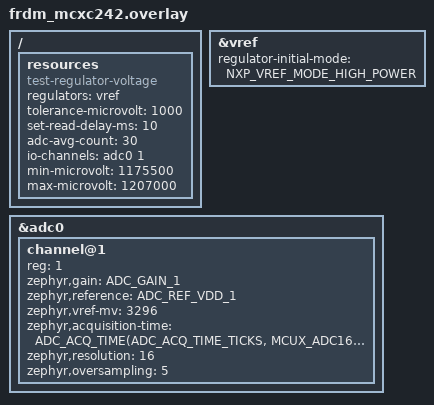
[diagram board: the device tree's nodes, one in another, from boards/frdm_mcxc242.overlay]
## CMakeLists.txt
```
# Copyright (c) 2022 Nordic Semiconductor ASA
# SPDX-License-Identifier: Apache-2.0

cmake_minimum_required(VERSION 3.28.0)
find_package(Zephyr REQUIRED HINTS $ENV{ZEPHYR_BASE})

project(regulator_voltage)

target_sources(app PRIVATE src/main.c)
```

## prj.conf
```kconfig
# Copyright (c) 2022 Nordic Semiconductor ASA
# SPDX-License-Identifier: Apache-2.0

CONFIG_ZTEST=y
CONFIG_ADC=y
CONFIG_REGULATOR=y
```

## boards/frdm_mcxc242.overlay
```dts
/*
 * Copyright 2025 NXP
 * SPDX-License-Identifier: Apache-2.0
 */

#include <zephyr/dt-bindings/regulator/nxp_vref.h>
#include <zephyr/dt-bindings/adc/mcux-adc16.h>

/* Connect J4-2 and J8-2 to test this case. */

/ {
	resources: resources {
		compatible = "test-regulator-voltage";
		regulators = <&vref>;
		tolerance-microvolt = <1000>;
		set-read-delay-ms = <10>;
		adc-avg-count = <30>;
		io-channels = <&adc0 1>;
		min-microvolt = <1175500>;
		max-microvolt = <1207000>;
	};
};

&vref {
	regulator-initial-mode = <NXP_VREF_MODE_HIGH_POWER>;
};

&adc0 {
	#address-cells = <1>;
	#size-cells = <0>;

	channel@1 {
		reg = <1>;
		zephyr,gain = "ADC_GAIN_1";
		zephyr,reference = "ADC_REF_VDD_1";
		zephyr,vref-mv = <3296>;
		zephyr,acquisition-time = <ADC_ACQ_TIME(ADC_ACQ_TIME_TICKS,
							MCUX_ADC16_ACQUISITION_TIME_24CYCLE)>;
		zephyr,resolution = <16>;
		zephyr,oversampling = <5>;
	};
};
```

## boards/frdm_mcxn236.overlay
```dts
/*
 * Copyright 2024-2025 NXP
 * SPDX-License-Identifier: Apache-2.0
 */

#include <zephyr/dt-bindings/adc/adc.h>
#include <zephyr/dt-bindings/adc/mcux-lpadc.h>
#include <zephyr/dt-bindings/regulator/nxp_vref.h>

/ {
	resources: resources {
		compatible = "test-regulator-voltage";
		regulators = <&vref>;
		tolerance-microvolt = <20000>;
		set-read-delay-ms = <1>;
		adc-avg-count = <10>;
		io-channels = <&lpadc0 0>;
		min-microvolt = <1000000>;
		max-microvolt = <2100000>;
	};
};

&vref {
	regulator-initial-mode = <NXP_VREF_MODE_HIGH_POWER>;
};

&lpadc0 {
	#address-cells = <1>;
	#size-cells = <0>;

	/* In this case, the LPADC reference source cannot be set to VREFO,
	 * switch the reference source to VDD_ANA. The user needs to measure the
	 * voltage of VDD_ANA pin to set the value of 'zephyr,vref-mv'.
	 */
	voltage-ref = <2>;

	channel@0 {
		reg = <0>;
		zephyr,gain = "ADC_GAIN_1";
		zephyr,reference = "ADC_REF_EXTERNAL0";
		/* VDD_ANA is not accurate to 3300mV, after measurement,
		 * the actual voltage is 3285mV.
		 */
		zephyr,vref-mv = <3285>;
		zephyr,acquisition-time = <ADC_ACQ_TIME(ADC_ACQ_TIME_TICKS, 7)>;
		zephyr,resolution = <12>;
		/* ADC0 channel 7 A-side is internally connected to VREFO. */
		zephyr,input-positive = <MCUX_LPADC_CH7A>;
	};
};
```

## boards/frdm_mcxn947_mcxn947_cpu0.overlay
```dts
/*
 * Copyright 2024-2025 NXP
 * SPDX-License-Identifier: Apache-2.0
 */

#include <zephyr/dt-bindings/adc/adc.h>
#include <zephyr/dt-bindings/adc/mcux-lpadc.h>
#include <zephyr/dt-bindings/regulator/nxp_vref.h>

/ {
	resources: resources {
		compatible = "test-regulator-voltage";
		regulators = <&vref>;
		tolerance-microvolt = <30000>;
		set-read-delay-ms = <1>;
		adc-avg-count = <10>;
		io-channels = <&lpadc0 0>;
		min-microvolt = <1000000>;
		max-microvolt = <2100000>;
	};
};

&vref {
	regulator-initial-mode = <NXP_VREF_MODE_HIGH_POWER>;
};

&lpadc0 {
	#address-cells = <1>;
	#size-cells = <0>;

	/* In this case, the LPADC reference source cannot be set to VREFO,
	 * switch the reference source to VDD_ANA. The user needs to measure the
	 * voltage of VDD_ANA pin to set the value of 'zephyr,vref-mv'.
	 */
	voltage-ref = <2>;

	channel@0 {
		reg = <0>;
		zephyr,gain = "ADC_GAIN_1";
		zephyr,reference = "ADC_REF_EXTERNAL0";
		/* VDD_ANA is not accurate to 3300mV, after measurement,
		 * the actual voltage is 3285mV.
		 */
		zephyr,vref-mv = <3285>;
		zephyr,acquisition-time = <ADC_ACQ_TIME(ADC_ACQ_TIME_TICKS, 7)>;
		zephyr,resolution = <12>;
		/* ADC0 channel 7 A-side is internally connected to VREFO. */
		zephyr,input-positive = <MCUX_LPADC_CH7A>;
	};
};
```

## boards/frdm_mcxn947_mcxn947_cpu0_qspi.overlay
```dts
/*
 * Copyright 2024-2025 NXP
 * SPDX-License-Identifier: Apache-2.0
 */

#include <zephyr/dt-bindings/adc/adc.h>
#include <zephyr/dt-bindings/adc/mcux-lpadc.h>
#include <zephyr/dt-bindings/regulator/nxp_vref.h>

/ {
	resources: resources {
		compatible = "test-regulator-voltage";
		regulators = <&vref>;
		tolerance-microvolt = <30000>;
		set-read-delay-ms = <1>;
		adc-avg-count = <10>;
		io-channels = <&lpadc0 0>;
		min-microvolt = <1000000>;
		max-microvolt = <2100000>;
	};
};

&vref {
	regulator-initial-mode = <NXP_VREF_MODE_HIGH_POWER>;
};

&lpadc0 {
	#address-cells = <1>;
	#size-cells = <0>;

	/* In this case, the LPADC reference source cannot be set to VREFO,
	 * switch the reference source to VDD_ANA. The user needs to measure the
	 * voltage of VDD_ANA pin to set the value of 'zephyr,vref-mv'.
	 */
	voltage-ref= <2>;

	channel@0 {
		reg = <0>;
		zephyr,gain = "ADC_GAIN_1";
		zephyr,reference = "ADC_REF_EXTERNAL0";
		/* VDD_ANA is not accurate to 3300mV, after measurement,
		 * the actual voltage is 3285mV.
		 */
		zephyr,vref-mv = <3285>;
		zephyr,acquisition-time = <ADC_ACQ_TIME(ADC_ACQ_TIME_TICKS, 7)>;
		zephyr,resolution = <12>;
		/* ADC0 channel 7 A-side is internally connected to VREFO. */
		zephyr,input-positive = <MCUX_LPADC_CH7A>;
	};
};
```

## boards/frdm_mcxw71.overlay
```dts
/*
 * Copyright 2024-2025 NXP
 * SPDX-License-Identifier: Apache-2.0
 */

#include <zephyr/dt-bindings/adc/adc.h>
#include <zephyr/dt-bindings/adc/mcux-lpadc.h>
#include <zephyr/dt-bindings/regulator/nxp_vref.h>

/ {
	resources: resources {
		compatible = "test-regulator-voltage";
		regulators = <&vref>;
		tolerance-microvolt = <20000>;
		set-read-delay-ms = <1>;
		adc-avg-count = <10>;
		io-channels = <&adc0 0>;
		min-microvolt = <1000000>;
		max-microvolt = <2100000>;
	};
};

&vref {
	regulator-initial-mode = <NXP_VREF_MODE_HIGH_POWER>;
};

&adc0 {
	#address-cells = <1>;
	#size-cells = <0>;

	/* In this case, the LPADC reference source cannot be set to VREFO,
	 * switch the reference source to VDD_ANA. The user needs to measure the
	 * voltage of VDD_ANA pin to set the value of 'zephyr,vref-mv'.
	 */
	voltage-ref = <0>;

	channel@0 {
		reg = <0>;
		zephyr,gain = "ADC_GAIN_1";
		zephyr,reference = "ADC_REF_EXTERNAL0";
		/* VDD_ANA is not accurate to 3300mV, after measurement,
		 * the actual voltage is 3285mV.
		 */
		zephyr,vref-mv = <3285>;
		zephyr,acquisition-time = <ADC_ACQ_TIME(ADC_ACQ_TIME_TICKS, 7)>;
		zephyr,resolution = <12>;
		/* ADC0 channel 23 A-side is internally connected to VREFO. */
		zephyr,input-positive = <MCUX_LPADC_CH23A>;
	};
};
```

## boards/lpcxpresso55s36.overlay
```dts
/*
 * Copyright 2023, 2025 NXP
 * SPDX-License-Identifier: Apache-2.0
 */

#include <zephyr/dt-bindings/adc/mcux-lpadc.h>
#include <zephyr/dt-bindings/regulator/nxp_vref.h>

/ {
	resources: resources {
		compatible = "test-regulator-voltage";
		regulators = <&vref0>;
		tolerance-microvolt = <20000>;
		set-read-delay-ms = <10>;
		adc-avg-count = <10>;
		io-channels = <&adc0 0>;
		min-microvolt = <1000000>;
		max-microvolt = <2100000>;
	};
};

&vref0 {
	regulator-initial-mode = <NXP_VREF_MODE_HIGH_POWER>;
};

&adc0 {
	#address-cells = <1>;
	#size-cells = <0>;

	/* In this case, the LPADC reference source cannot be set to VREFO,
	 * switch the reference source to VDDA. The user needs to measure the
	 * voltage of VDDA pin to set the value of 'zephyr,vref-mv'.
	 */
	voltage-ref = <2>;

	channel@0 {
		reg = <0>;
		zephyr,gain = "ADC_GAIN_1";
		zephyr,reference = "ADC_REF_EXTERNAL0";
		/* VDDA is not accurate to 3300mV, after measurement,
		 * the actual voltage is 3285mV.
		 */
		zephyr,vref-mv = <3285>;
		zephyr,acquisition-time = <ADC_ACQ_TIME(ADC_ACQ_TIME_TICKS, 7)>;
		zephyr,resolution = <12>;
		/* ADC0 channel 5 A-side is internally connected to VREFO. */
		zephyr,input-positive = <MCUX_LPADC_CH5A>;
	};
};
```

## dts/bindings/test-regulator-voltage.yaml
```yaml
# Copyright 2022 Nordic Semiconductor ASA
# SPDX-License-Identifier: Apache-2.0

description: |
    This binding provides resources required to build and run the
    tests/drivers/regulator/voltage test in Zephyr.

compatible: "test-regulator-voltage"

properties:
  regulators:
    type: phandles
    required: true
    description: |
      Regulators to be tested. Each entry must have a matching ADC entry in
      io-channels.

  io-channels:
    type: phandle-array
    required: true
    description: |
      ADC channels to be used. Each entry must have a matching entry in
      regulators.

  tolerance-microvolt:
    type: array
    required: true
    description: |
      Tolerance (+/-) when reading configured voltages using ADC. This should
      be set at most to the regulator resolution. Some noisy regulators may
      require more, though. Each entry must have a matching entry in
      regulators.

  adc-avg-count:
    type: int
    default: 1
    description: |
      Number of ADC readings to average. Defaults to 1 (no average).

  set-read-delay-ms:
    type: int
    default: 0
    description: |
      Delay between voltage set and ADC read. Defaults to 0 (no delay).

  min-microvolt:
    type: int
    default: -2147483648
    description: |
      Specifies the minimum voltage at which the test will run, in microvolts.
      Used to filter out ranges that cannot be tested correctly in the configuration.

  max-microvolt:
    type: int
    default: 2147483647
    description: |
      Specifies the maximum voltage at which the test will run, in microvolts.
      Used to filter out ranges that cannot be tested correctly in the configuration.
```

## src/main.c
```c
/*
 * Copyright (c) 2022 Nordic Semiconductor ASA
 * SPDX-License-Identifier: Apache-2.0
 */

#include <zephyr/device.h>
#include <zephyr/devicetree.h>
#include <zephyr/drivers/adc.h>
#include <zephyr/drivers/regulator.h>
#include <zephyr/sys/util.h>
#include <zephyr/ztest.h>

#define ADC_INIT(node_id, prop, idx) \
	ADC_DT_SPEC_GET_BY_IDX(node_id, idx),

static const struct device *regs[] = {
	DT_FOREACH_PROP_ELEM_SEP(DT_NODELABEL(resources), regulators, DEVICE_DT_GET_BY_IDX, (,))
};

static const struct adc_dt_spec adc_chs[] = {
	DT_FOREACH_PROP_ELEM(DT_NODELABEL(resources), io_channels, ADC_INIT)
};

static const int32_t tols[] =
	DT_PROP(DT_NODELABEL(resources), tolerance_microvolt);

static const unsigned int adc_avg_count = DT_PROP(DT_NODELABEL(resources),
						  adc_avg_count);
static const int32_t set_read_delay_ms = DT_PROP(DT_NODELABEL(resources),
						 set_read_delay_ms);

static const int32_t min_microvolt = DT_PROP(DT_NODELABEL(resources), min_microvolt);
static const int32_t max_microvolt = DT_PROP(DT_NODELABEL(resources), max_microvolt);

ZTEST(regulator_voltage, test_output_voltage)
{
	int16_t buf;
	struct adc_sequence sequence = {
		.buffer = &buf,
		.buffer_size = sizeof(buf),
	};

	for (size_t i = 0U; i < ARRAY_SIZE(regs); i++) {
		int ret;
		unsigned int volt_cnt;
		int32_t volt_uv;

		ret = adc_sequence_init_dt(&adc_chs[i], &sequence);
		zassert_equal(ret, 0);

		volt_cnt = regulator_count_voltages(regs[i]);
		zassume_not_equal(volt_cnt, 0U);

		TC_PRINT("Testing %s, %u voltage/s (tolerance: %d uV)\n",
			 regs[i]->name, volt_cnt, tols[i]);

		ret = regulator_enable(regs[i]);
		zassert_equal(ret, 0);

		for (unsigned int j = 0U; j < volt_cnt; j++) {
			int32_t val_uv = 0;

			(void)regulator_list_voltage(regs[i], j, &volt_uv);
			/* Check if voltage is outside user constraints */
			if (!regulator_is_supported_voltage(regs[i],
				volt_uv, volt_uv)) {
				continue;
			}

			if ((volt_uv < min_microvolt) || (volt_uv > max_microvolt)) {
				TC_PRINT("Skip: %d uV\n", volt_uv);
				continue;
			}

			ret = regulator_set_voltage(regs[i], volt_uv, volt_uv);
			zassert_equal(ret, 0);

			if (set_read_delay_ms > 0) {
				k_msleep(set_read_delay_ms);
			}

			for (unsigned int k = 0U; k < adc_avg_count; k++) {
				ret = adc_read_dt(&adc_chs[i], &sequence);
				zassert_equal(ret, 0);

				val_uv += buf;
			}

			val_uv /= (int32_t)adc_avg_count;

			ret = adc_raw_to_microvolts_dt(&adc_chs[i], &val_uv);
			zassert_equal(ret, 0);

			TC_PRINT("Set: %d, read: %d uV\n", volt_uv, val_uv);

			zassert_between_inclusive(val_uv,
						  volt_uv - tols[i],
						  volt_uv + tols[i]);
		}

		ret = regulator_disable(regs[i]);
		zassert_equal(ret, 0);
	}
}

void *setup(void)
{
	zassert_equal(ARRAY_SIZE(regs), ARRAY_SIZE(adc_chs));
	zassert_equal(ARRAY_SIZE(regs), ARRAY_SIZE(tols));

	for (size_t i = 0U; i < ARRAY_SIZE(regs); i++) {
		zassert_true(device_is_ready(regs[i]));
		zassert_true(adc_is_ready_dt(&adc_chs[i]));
		zassert_equal(adc_channel_setup_dt(&adc_chs[i]), 0);
	}

	return NULL;
}

ZTEST_SUITE(regulator_voltage, NULL, setup, NULL, NULL, NULL);
```
